AUTOSAR XML (schema 4-2-1)
package /RootP_IntDcm
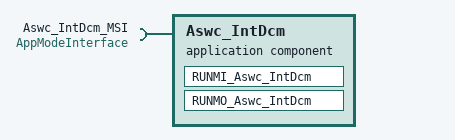
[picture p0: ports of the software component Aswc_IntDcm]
  application sw component type Aswc_IntDcm
    require port Aswc_IntDcm_MSI: required-interface=AppModeInterface
    behavior IB_Aswc_IntDcm: data-type-mapping=ApplicationModeMapping, handle-termination-and-restart=NO-SUPPORT
      swc mode switch event RUNMI_Aswc_IntDcm_NvmIn: start-on-event=RUNMI_Aswc_IntDcm, activation=ON-ENTRY, mode=Aswc_IntDcm_MSI.AppMode.APP_SYNC_INIT1
      swc mode switch event RUNMO_Aswc_IntDcm_NvmOut: start-on-event=RUNMO_Aswc_IntDcm, activation=ON-ENTRY, mode=Aswc_IntDcm_MSI.AppMode.APP_ON
      runnable RUNMI_Aswc_IntDcm
        data-write-access:
          253 x access:
            Dwa_CFG_DEF_VEHICULE: accessed-variable=PRP_SR_CFG_DEF_VEHICULE.CFG_DEF_VEHICULE
            Dwa_CFG_PRESENCE_ETSR: accessed-variable=PRP_SR_CFG_PRESENCE_ETSR.CFG_PRESENCE_ETSR
            Dwa_CFG_NAV_POI_RADAR: accessed-variable=PRP_SR_CFG_NAV_POI_RADAR.CFG_NAV_POI_RADAR
            Dwa_CFG_OPT_ANTICIPATED_PLV: accessed-variable=PRP_SR_CFG_OPT_ANTICIPATED_PLV.CFG_OPT_ANTICIPATED_PLV
            Dwa_CFG_TYPE_ILV: accessed-variable=PRP_SR_CFG_TYPE_ILV.CFG_TYPE_ILV
            Dwa_CFG_OPTION_HADC: accessed-variable=PRP_SR_CFG_OPTION_HADC.CFG_OPTION_HADC
            Dwa_CFG_TYPE_LANE_ASSIST: accessed-variable=PRP_SR_CFG_TYPE_LANE_ASSIST.CFG_TYPE_LANE_ASSIST
            Dwa_CFG_TYPE_DRIVER_ASSIST: accessed-variable=PRP_SR_CFG_TYPE_DRIVER_ASSIST.CFG_TYPE_DRIVER_ASSIST
            Dwa_CFG_PRESENCE_CABIN_AQI_SENSOR: accessed-variable=PRP_SR_CFG_PRESENCE_CABIN_AQI_SENSOR.CFG_PRESENCE_CABIN_AQI_SENSOR
            Dwa_CFG_MODUL_STTCONFORT: accessed-variable=PRP_SR_CFG_MODUL_STTCONFORT.CFG_MODUL_STTCONFORT
            Dwa_CFG_RAPENTR: accessed-variable=PRP_SR_CFG_RAPENTR.CFG_RAPENTR
            Dwa_CFG_MODUL_POLLUT: accessed-variable=PRP_SR_CFG_MODUL_POLLUT.CFG_MODUL_POLLUT
            Dwa_CFG_MODUL_CPR: accessed-variable=PRP_SR_CFG_MODUL_CPR.CFG_MODUL_CPR
            Dwa_CFG_MODUL_CTP: accessed-variable=PRP_SR_CFG_MODUL_CTP.CFG_MODUL_CTP
            Dwa_CFG_MODUL_DEBIT_AERO: accessed-variable=PRP_SR_CFG_MODUL_DEBIT_AERO.CFG_MODUL_DEBIT_AERO
            Dwa_CFG_MODUL_FMUX: accessed-variable=PRP_SR_CFG_MODUL_FMUX.CFG_MODUL_FMUX
            Dwa_CFG_MODUL_RECHAUFFEUR: accessed-variable=PRP_SR_CFG_MODUL_RECHAUFFEUR.CFG_MODUL_RECHAUFFEUR
            Dwa_CFG_MODUL_PROG_PRECOND: accessed-variable=PRP_SR_CFG_MODUL_PROG_PRECOND.CFG_MODUL_PROG_PRECOND
            Dwa_CFG_PRESENCE_CIELO: accessed-variable=PRP_SR_CFG_PRESENCE_CIELO.CFG_PRESENCE_CIELO
            Dwa_CFG_MODUL_TAS: accessed-variable=PRP_SR_CFG_MODUL_TAS.CFG_MODUL_TAS
            Dwa_CFG_MODUL_SOL: accessed-variable=PRP_SR_CFG_MODUL_SOL.CFG_MODUL_SOL
            Dwa_CFG_MODUL_DCT: accessed-variable=PRP_SR_CFG_MODUL_DCT.CFG_MODUL_DCT
            Dwa_CFG_TYPE_CLIM: accessed-variable=PRP_SR_CFG_TYPE_CLIM.CFG_TYPE_CLIM
            Dwa_CFG_TYPE_ARCHI_IHM_CLIM: accessed-variable=PRP_SR_CFG_TYPE_ARCHI_IHM_CLIM.CFG_TYPE_ARCHI_IHM_CLIM
            Dwa_CFG_TYPE_IHM_DISTRIB_AV_TACT: accessed-variable=PRP_SR_CFG_TYPE_IHM_DISTRIB_AV_TACT.CFG_TYPE_IHM_DISTRIB_AV_TACT
            Dwa_CFG_TYPE_IHM_ENTREE_AIR_PHYS: accessed-variable=PRP_SR_CFG_TYPE_IHM_ENTREE_AIR_PHYS.CFG_TYPE_IHM_ENTREE_AIR_PHYS
            Dwa_CFG_TYPE_IHM_PULSEUR_AR: accessed-variable=PRP_SR_CFG_TYPE_IHM_PULSEUR_AR.CFG_TYPE_IHM_PULSEUR_AR
            Dwa_CFG_TYPE_IHM_PULSEUR_AV_PHYS: accessed-variable=PRP_SR_CFG_TYPE_IHM_PULSEUR_AV_PHYS.CFG_TYPE_IHM_PULSEUR_AV_PHYS
            Dwa_CFG_TYPE_IHM_PULSEUR_AV_TACT: accessed-variable=PRP_SR_CFG_TYPE_IHM_PULSEUR_AV_TACT.CFG_TYPE_IHM_PULSEUR_AV_TACT
            Dwa_CFG_TYPE_IHM_PULSEUR_RG3: accessed-variable=PRP_SR_CFG_TYPE_IHM_PULSEUR_RG3.CFG_TYPE_IHM_PULSEUR_RG3
            Dwa_CFG_TYPE_IHM_TEMP_AV_PHYS: accessed-variable=PRP_SR_CFG_TYPE_IHM_TEMP_AV_PHYS.CFG_TYPE_IHM_TEMP_AV_PHYS
            Dwa_CFG_TYPE_IHM_TEMP_AV_TACT: accessed-variable=PRP_SR_CFG_TYPE_IHM_TEMP_AV_TACT.CFG_TYPE_IHM_TEMP_AV_TACT
            Dwa_CFG_TYPE_IHM_TYPAGE_AUTO: accessed-variable=PRP_SR_CFG_TYPE_IHM_TYPAGE_AUTO.CFG_TYPE_IHM_TYPAGE_AUTO
            Dwa_CFG_TYPE_FAP: accessed-variable=PRP_SR_CFG_TYPE_FAP.CFG_TYPE_FAP
            Dwa_CFG_NumTable_NH: accessed-variable=PRP_SR_CFG_NumTable_NH.CFG_NumTable_NH
            Dwa_CFG_ORIGINE_NHUILE: accessed-variable=PRP_SR_CFG_ORIGINE_NHUILE.CFG_ORIGINE_NHUILE
            Dwa_CFG_PRESENCE_AUTO_INHIB_RBG_PASS: accessed-variable=PRP_SR_CFG_PRESENCE_AUTO_INHIB_RBG_PASS.CFG_PRESENCE_AUTO_INHIB_RBG_PASS
            Dwa_CFG_PRESENCE_DSG: accessed-variable=PRP_SR_CFG_PRESENCE_DSG.CFG_PRESENCE_DSG
            Dwa_CFG_TYPE_PUSH_DSGI: accessed-variable=PRP_SR_CFG_TYPE_PUSH_DSGI.CFG_TYPE_PUSH_DSGI
            Dwa_CFG_PRESENCE_AVE: accessed-variable=PRP_SR_CFG_PRESENCE_AVE.CFG_PRESENCE_AVE
            Dwa_CFG_TYPE_CHAINE_TRACTION: accessed-variable=PRP_SR_CFG_TYPE_CHAINE_TRACTION.CFG_TYPE_CHAINE_TRACTION
            Dwa_CFG_TYPE_DEMARRAGE: accessed-variable=PRP_SR_CFG_TYPE_DEMARRAGE.CFG_TYPE_DEMARRAGE
            Dwa_CFG_TYPE_GMP: accessed-variable=PRP_SR_CFG_TYPE_GMP.CFG_TYPE_GMP
            Dwa_CFG_PRESENCE_FARC: accessed-variable=PRP_SR_CFG_PRESENCE_FARC.CFG_PRESENCE_FARC
            Dwa_CFG_PRESENCE_ARC: accessed-variable=PRP_SR_CFG_PRESENCE_ARC.CFG_PRESENCE_ARC
            Dwa_CFG_AMVAR: accessed-variable=PRP_SR_CFG_AMVAR.CFG_AMVAR
            Dwa_TYPE_HMI_MODE_SELECTOR: accessed-variable=PRP_SR_TYPE_HMI_MODE_SELECTOR.TYPE_HMI_MODE_SELECTOR
            Dwa_CFG_PRESENCE_MODE_ECO_DYN: accessed-variable=PRP_SR_CFG_PRESENCE_MODE_ECO_DYN.CFG_PRESENCE_MODE_ECO_DYN
            Dwa_CFG_PRESENCE_MEAP: accessed-variable=PRP_SR_CFG_PRESENCE_MEAP.CFG_PRESENCE_MEAP
            Dwa_CFG_POLYSENSORIAL_PACK: accessed-variable=PRP_SR_CFG_POLYSENSORIAL_PACK.CFG_POLYSENSORIAL_PACK
            Dwa_CFG_PRESENCE_MODE_SPORT_DYN: accessed-variable=PRP_SR_CFG_PRESENCE_MODE_SPORT_DYN.CFG_PRESENCE_MODE_SPORT_DYN
            Dwa_CFG_OPTION_SONDE_EAU_GAZOLE: accessed-variable=PRP_SR_CFG_OPTION_SONDE_EAU_GAZOLE.CFG_OPTION_SONDE_EAU_GAZOLE
            Dwa_CFG_TYPE_PACK_DYN: accessed-variable=PRP_SR_CFG_TYPE_PACK_DYN.CFG_TYPE_PACK_DYN
            Dwa_CFG_AUTOR_MAP_HMI: accessed-variable=PRP_SR_CFG_AUTOR_MAP_HMI.CFG_AUTOR_MAP_HMI
            Dwa_CFG_FCT_GSI: accessed-variable=PRP_SR_CFG_FCT_GSI.CFG_FCT_GSI
            Dwa_CFG_TYPE_BOITE: accessed-variable=PRP_SR_CFG_TYPE_BOITE.CFG_TYPE_BOITE
            Dwa_CFG_TYPE_SC: accessed-variable=PRP_SR_CFG_TYPE_SC.CFG_TYPE_SC
            Dwa_CFG_ACQ_PUSH_ESP: accessed-variable=PRP_SR_CFG_ACQ_PUSH_ESP.CFG_ACQ_PUSH_ESP
            Dwa_CFG_PRESENCE_ASR_PLUS: accessed-variable=PRP_SR_CFG_PRESENCE_ASR_PLUS.CFG_PRESENCE_ASR_PLUS
            Dwa_CFG_OPTION_HBB_HBC: accessed-variable=PRP_SR_CFG_OPTION_HBB_HBC.CFG_OPTION_HBB_HBC
            Dwa_CFG_OPTION_PLV: accessed-variable=PRP_SR_CFG_OPTION_PLV.CFG_OPTION_PLV
            Dwa_CFG_PRESENCE_LVVRVV: accessed-variable=PRP_SR_CFG_PRESENCE_LVVRVV.CFG_PRESENCE_LVVRVV
            Dwa_CFG_TYPE_ACC: accessed-variable=PRP_SR_CFG_TYPE_ACC.CFG_TYPE_ACC
            Dwa_CFG_TYPE_TARGET_DETECTION: accessed-variable=PRP_SR_CFG_TYPE_TARGET_DETECTION.CFG_TYPE_TARGET_DETECTION
            Dwa_CFG_TYPE_AQUI_PUSH_STT: accessed-variable=PRP_SR_CFG_TYPE_AQUI_PUSH_STT.CFG_TYPE_AQUI_PUSH_STT
            Dwa_CFG_TYPE_STT: accessed-variable=PRP_SR_CFG_TYPE_STT.CFG_TYPE_STT
            Dwa_CFG_TypeCPK: accessed-variable=PRP_SR_CFG_TypeCPK.CFG_TypeCPK
            Dwa_CFG_OPTION_SAM: accessed-variable=PRP_SR_CFG_OPTION_SAM.CFG_OPTION_SAM
            Dwa_CFG_PRESENCE_PUSH_SAM: accessed-variable=PRP_SR_CFG_PRESENCE_PUSH_SAM.CFG_PRESENCE_PUSH_SAM
            Dwa_CFG_OPTION_DOP: accessed-variable=PRP_SR_CFG_OPTION_DOP.CFG_OPTION_DOP
            Dwa_CFG_PRESENCE_ECOACH: accessed-variable=PRP_SR_CFG_PRESENCE_ECOACH.CFG_PRESENCE_ECOACH
            Dwa_CFG_NIV_ALERTE_MINI_CARB: accessed-variable=PRP_SR_CFG_NIV_ALERTE_MINI_CARB.CFG_NIV_ALERTE_MINI_CARB
            Dwa_C7D_NIV_CARB_CRITIQUE: accessed-variable=PRP_SR_C7D_NIV_CARB_CRITIQUE.C7D_NIV_CARB_CRITIQUE
            Dwa_CFG_NUM_TABLE_CARB: accessed-variable=PRP_SR_CFG_NUM_TABLE_CARB.CFG_NUM_TABLE_CARB
            Dwa_CfgTypeLocksSteering: accessed-variable=PRP_SR_CfgTypeLocksSteering.CfgTypeLocksSteering
            Dwa_CFG_OPTION_BLUETOOTH: accessed-variable=PRP_SR_CFG_OPTION_BLUETOOTH.CFG_OPTION_BLUETOOTH
            Dwa_CFG_OPTION_BAA: accessed-variable=PRP_SR_CFG_OPTION_BAA.CFG_OPTION_BAA
            Dwa_CfgTypeTrunkPushInterior: accessed-variable=PRP_SR_CfgTypeTrunkPushInterior.CfgTypeTrunkPushInterior
            Dwa_CfgTypeRearOpening: accessed-variable=PRP_SR_CfgTypeRearOpening.CfgTypeRearOpening
            Dwa_CFG_VOLET_MOTORISE: accessed-variable=PRP_SR_CFG_VOLET_MOTORISE.CFG_VOLET_MOTORISE
            Dwa_CfgSelectivityDoors: accessed-variable=PRP_SR_CfgSelectivityDoors.CfgSelectivityDoors
            Dwa_CFG_STEERING_WHEEL_POSITION: accessed-variable=PRP_SR_CFG_STEERING_WHEEL_POSITION.CFG_STEERING_WHEEL_POSITION
            Dwa_CFG_CONDA: accessed-variable=PRP_SR_CFG_CONDA.CFG_CONDA
            Dwa_CFG_PLIP_TOUCH_3_FUNCTION: accessed-variable=PRP_SR_CFG_PLIP_TOUCH_3_FUNCTION.CFG_PLIP_TOUCH_3_FUNCTION
            Dwa_CFG_PLIP_WL_FUNCTIONNALITY: accessed-variable=PRP_SR_CFG_PLIP_WL_FUNCTIONNALITY.CFG_PLIP_WL_FUNCTIONNALITY
            Dwa_CFG_PLIP_WL_BEHAVIOR: accessed-variable=PRP_SR_CFG_PLIP_WL_BEHAVIOR.CFG_PLIP_WL_BEHAVIOR
            Dwa_CFG_PLIP_PRESS_TYPE_TOUCH_3: accessed-variable=PRP_SR_CFG_PLIP_PRESS_TYPE_TOUCH_3.CFG_PLIP_PRESS_TYPE_TOUCH_3
            Dwa_CFG_DRIVER_LOCK_TYPE: accessed-variable=PRP_SR_CFG_DRIVER_LOCK_TYPE.CFG_DRIVER_LOCK_TYPE
            Dwa_CFG_FUEL_FLAP_LOCK_TYPE: accessed-variable=PRP_SR_CFG_FUEL_FLAP_LOCK_TYPE.CFG_FUEL_FLAP_LOCK_TYPE
            Dwa_CFG_HOOD_LOCK_TYPE: accessed-variable=PRP_SR_CFG_HOOD_LOCK_TYPE.CFG_HOOD_LOCK_TYPE
            Dwa_CFG_REAR_LEFT_LOCK_TYPE: accessed-variable=PRP_SR_CFG_REAR_LEFT_LOCK_TYPE.CFG_REAR_LEFT_LOCK_TYPE
            Dwa_CFG_REAR_RIGHT_LOCK_TYPE: accessed-variable=PRP_SR_CFG_REAR_RIGHT_LOCK_TYPE.CFG_REAR_RIGHT_LOCK_TYPE
            Dwa_CFG_OPTION_SUNROOF: accessed-variable=PRP_SR_CFG_OPTION_SUNROOF.CFG_OPTION_SUNROOF
            Dwa_CfgRearViewMirrorIndexingReverseGear: accessed-variable=PRP_SR_CfgRearViewMirrorIndexingReverseGear.CfgRearViewMirrorIndexingReverseGear
            Dwa_CFG_OPTION_SIEGE_CLIM: accessed-variable=PRP_SR_CFG_OPTION_SIEGE_CLIM.CFG_OPTION_SIEGE_CLIM
            Dwa_CFG_PRES_VOLANT_CHAUF: accessed-variable=PRP_SR_CFG_PRES_VOLANT_CHAUF.CFG_PRES_VOLANT_CHAUF
            Dwa_CFG_TYPE_SOC: accessed-variable=PRP_SR_CFG_TYPE_SOC.CFG_TYPE_SOC
            Dwa_CFG_OPTION_VISION_NOCTURNE: accessed-variable=PRP_SR_CFG_OPTION_VISION_NOCTURNE.CFG_OPTION_VISION_NOCTURNE
            Dwa_CFG_AUTOR_MAP_ECLI: accessed-variable=PRP_SR_CFG_AUTOR_MAP_ECLI.CFG_AUTOR_MAP_ECLI
            Dwa_CFG_POLYCHROME_AMB: accessed-variable=PRP_SR_CFG_POLYCHROME_AMB.CFG_POLYCHROME_AMB
            Dwa_CFG_OPTION_AFS: accessed-variable=PRP_SR_CFG_OPTION_AFS.CFG_OPTION_AFS
            Dwa_CFG_OPTION_ECL_INTERSEC: accessed-variable=PRP_SR_CFG_OPTION_ECL_INTERSEC.CFG_OPTION_ECL_INTERSEC
            Dwa_CFG_OPTION_ECL_VIR_STAT: accessed-variable=PRP_SR_CFG_OPTION_ECL_VIR_STAT.CFG_OPTION_ECL_VIR_STAT
            Dwa_CFG_OPTION_ANTIBR_AV: accessed-variable=PRP_SR_CFG_OPTION_ANTIBR_AV.CFG_OPTION_ANTIBR_AV
            Dwa_CFG_TypeEclairageAV: accessed-variable=PRP_SR_CFG_TypeEclairageAV.CFG_TypeEclairageAV
            Dwa_CFG_PRESENCE_BSG_RQ: accessed-variable=PRP_SR_CFG_PRESENCE_BSG_RQ.CFG_PRESENCE_BSG_RQ
            Dwa_CFG_INHIB_MOVING_EFFECT: accessed-variable=PRP_SR_CFG_INHIB_MOVING_EFFECT.CFG_INHIB_MOVING_EFFECT
            Dwa_CFG_FONCTION_AHB: accessed-variable=PRP_SR_CFG_FONCTION_AHB.CFG_FONCTION_AHB
            Dwa_CFG_OPTION_AAF: accessed-variable=PRP_SR_CFG_OPTION_AAF.CFG_OPTION_AAF
            Dwa_CFG_TYPE_COMODO: accessed-variable=PRP_SR_CFG_TYPE_COMODO.CFG_TYPE_COMODO
            Dwa_CFG_Barrette_TNB_sur_LIN: accessed-variable=PRP_SR_CFG_Barrette_TNB_sur_LIN.CFG_Barrette_TNB_sur_LIN
            Dwa_CFG_INHIB_DIAG_TNB_COND: accessed-variable=PRP_SR_CFG_INHIB_DIAG_TNB_COND.CFG_INHIB_DIAG_TNB_COND
            Dwa_CFG_INHIB_DIAG_TNB_PAR2C: accessed-variable=PRP_SR_CFG_INHIB_DIAG_TNB_PAR2C.CFG_INHIB_DIAG_TNB_PAR2C
            Dwa_CFG_INHIB_DIAG_TNB_PAR2D: accessed-variable=PRP_SR_CFG_INHIB_DIAG_TNB_PAR2D.CFG_INHIB_DIAG_TNB_PAR2D
            Dwa_CFG_INHIB_DIAG_TNB_PAR2G: accessed-variable=PRP_SR_CFG_INHIB_DIAG_TNB_PAR2G.CFG_INHIB_DIAG_TNB_PAR2G
            Dwa_CFG_OPTION_TAXI: accessed-variable=PRP_SR_CFG_OPTION_TAXI.CFG_OPTION_TAXI
            Dwa_CFG_INHIB_DIAG_TNB_PAV: accessed-variable=PRP_SR_CFG_INHIB_DIAG_TNB_PAV.CFG_INHIB_DIAG_TNB_PAV
            Dwa_CFG_NAPPE_DETECTION_PASS: accessed-variable=PRP_SR_CFG_NAPPE_DETECTION_PASS.CFG_NAPPE_DETECTION_PASS
            Dwa_CFG_NBR_CNB: accessed-variable=PRP_SR_CFG_NBR_CNB.CFG_NBR_CNB
            Dwa_CFG_TYPE_PRES_PASS_SENSOR: accessed-variable=PRP_SR_CFG_TYPE_PRES_PASS_SENSOR.CFG_TYPE_PRES_PASS_SENSOR
            Dwa_CFG_PRESENCE_OPTION_MEMORISATION: accessed-variable=PRP_SR_CFG_PRESENCE_OPTION_MEMORISATION.CFG_PRESENCE_OPTION_MEMORISATION
            Dwa_CFG_WELCOME_DRIVER_SEAT_FUNCTION: accessed-variable=PRP_SR_CFG_WELCOME_DRIVER_SEAT_FUNCTION.CFG_WELCOME_DRIVER_SEAT_FUNCTION
            Dwa_CFG_OPTION_MASSAGE: accessed-variable=PRP_SR_CFG_OPTION_MASSAGE.CFG_OPTION_MASSAGE
            Dwa_CFG_PRESENCE_VTH: accessed-variable=PRP_SR_CFG_PRESENCE_VTH.CFG_PRESENCE_VTH
            Dwa_CFG_MEMO_REGL_RETROS: accessed-variable=PRP_SR_CFG_MEMO_REGL_RETROS.CFG_MEMO_REGL_RETROS
            Dwa_CFG_PRESENCE_PBC: accessed-variable=PRP_SR_CFG_PRESENCE_PBC.CFG_PRESENCE_PBC
            Dwa_CFG_CLIMAT: accessed-variable=PRP_SR_CFG_CLIMAT.CFG_CLIMAT
            Dwa_CfgTypeFrontDefrost: accessed-variable=PRP_SR_CfgTypeFrontDefrost.CfgTypeFrontDefrost
            Dwa_CFG_TYPE_MODUL_OPTI_VIDE: accessed-variable=PRP_SR_CFG_TYPE_MODUL_OPTI_VIDE.CFG_TYPE_MODUL_OPTI_VIDE
            Dwa_CfgSweepingCourtesy: accessed-variable=PRP_SR_CfgSweepingCourtesy.CfgSweepingCourtesy
            Dwa_CfgRainSensor: accessed-variable=PRP_SR_CfgRainSensor.CfgRainSensor
            Dwa_SCR_AFFICH_POI_ADBLUE: accessed-variable=PRP_SR_SCR_AFFICH_POI_ADBLUE.SCR_AFFICH_POI_ADBLUE
            Dwa_CFG_PRESENCE_SCR: accessed-variable=PRP_SR_CFG_PRESENCE_SCR.CFG_PRESENCE_SCR
            Dwa_CFG_DISPO_PSEUDO_CONSO_CARB: accessed-variable=PRP_SR_CFG_DISPO_PSEUDO_CONSO_CARB.CFG_DISPO_PSEUDO_CONSO_CARB
            Dwa_CFG_EngineMaintType: accessed-variable=PRP_SR_CFG_EngineMaintType.CFG_EngineMaintType
            Dwa_M230_TimeFirstMaint: accessed-variable=PRP_SR_M230_TimeFirstMaint.M230_TimeFirstMaint
            Dwa_M230_TimeOtherMaint: accessed-variable=PRP_SR_M230_TimeOtherMaint.M230_TimeOtherMaint
            Dwa_M230_KmFirstMaint: accessed-variable=PRP_SR_M230_KmFirstMaint.M230_KmFirstMaint
            Dwa_M230_KmOtherMaint: accessed-variable=PRP_SR_M230_KmOtherMaint.M230_KmOtherMaint
            Dwa_M230_KmOrTimeMaint: accessed-variable=PRP_SR_M230_KmOrTimeMaint.M230_KmOrTimeMaint
            Dwa_CFG_DISTRACTION_MODE: accessed-variable=PRP_SR_CFG_DISTRACTION_MODE.CFG_DISTRACTION_MODE
            Dwa_CFG_PresenceCRT: accessed-variable=PRP_SR_CFG_PresenceCRT.CFG_PresenceCRT
            Dwa_CFG_TYPE_BTEL: accessed-variable=PRP_SR_CFG_TYPE_BTEL.CFG_TYPE_BTEL
            Dwa_CFG_SOFTWARE_UPDATE_CAPABILITY: accessed-variable=PRP_SR_CFG_SOFTWARE_UPDATE_CAPABILITY.CFG_SOFTWARE_UPDATE_CAPABILITY
            Dwa_DiagCodeVIN_01: accessed-variable=PRP_SR_DiagCodeVIN.DiagCodeVIN_{01..17}
            Dwa_CFG_SMARTDEVICE_BY_SDCM: accessed-variable=PRP_SR_CFG_SMARTDEVICE_BY_SDCM.CFG_SMARTDEVICE_BY_SDCM
            Dwa_CFG_AUTOR_MAP_INVIO: accessed-variable=PRP_SR_CFG_AUTOR_MAP_INVIO.CFG_AUTOR_MAP_INVIO
            Dwa_CFG_GEN_RSK16: accessed-variable=PRP_SR_CFG_GEN_RSK16.CFG_GEN_RSK16
            Dwa_CFG_OPTION_WLC: accessed-variable=PRP_SR_CFG_OPTION_WLC.CFG_OPTION_WLC
            Dwa_CFG_TYPE_CLE: accessed-variable=PRP_SR_CFG_TYPE_CLE.CFG_TYPE_CLE
            Dwa_CFG_ALARME_2NDE_MONTE: accessed-variable=PRP_SR_CFG_ALARME_2NDE_MONTE.CFG_ALARME_2NDE_MONTE
            Dwa_CFG_INHIB_VOLUMETRIE: accessed-variable=PRP_SR_CFG_INHIB_VOLUMETRIE.CFG_INHIB_VOLUMETRIE
            Dwa_CFG_PRESENCE_MUS_LIN: accessed-variable=PRP_SR_CFG_PRESENCE_MUS_LIN.CFG_PRESENCE_MUS_LIN
            Dwa_CFG_PRESENCE_SIRENE_LIN: accessed-variable=PRP_SR_CFG_PRESENCE_SIRENE_LIN.CFG_PRESENCE_SIRENE_LIN
            Dwa_CFG_TYPE_ALARME: accessed-variable=PRP_SR_CFG_TYPE_ALARME.CFG_TYPE_ALARME
            Dwa_CFG_OPTIONS_TLM: accessed-variable=PRP_SR_CFG_OPTIONS_TLM.CFG_OPTIONS_TLM
            Dwa_CFG_PROCESS_USINE_{01..06}: accessed-variable=PRP_SR_CFG_PROCESS_USINE_{01..06}.CFG_PROCESS_USINE_{01..06}
            Dwa_CFG_DATE_TELECODAGE_1: accessed-variable=PRP_SR_CFG_DATE_TELECODAGE_{1..3}.CFG_DATE_TELECODAGE_{1..3}
            Dwa_CFG_DATE_TELECODAGE_1: accessed-variable=PRP_SR_CFG_SIGNATURE_OUTIL_{1..3}.CFG_SIGNATURE_OUTIL_{1..3}
            Dwa_CFG_DATE_TELECODAGE_1: accessed-variable=PRP_SR_CFG_SITE_TELECODAGE.CFG_SITE_TELECODAGE
            Dwa_CFG_UCE_{001..026}: accessed-variable=PRP_SR_CFG_UCE_{001..026}.CFG_UCE_{001..026}
            Dwa_CFG_UCE_{028..069}: accessed-variable=PRP_SR_CFG_UCE_{028..069}.CFG_UCE_{028..069}
      runnable RUNMO_Aswc_IntDcm
        data-read-access:
          253 x access:
            Dra_CFG_DEF_VEHICULE: accessed-variable=PRP_SR_CFG_DEF_VEHICULE.CFG_DEF_VEHICULE
            Dra_CFG_PRESENCE_ETSR: accessed-variable=PRP_SR_CFG_PRESENCE_ETSR.CFG_PRESENCE_ETSR
            Dra_CFG_NAV_POI_RADAR: accessed-variable=PRP_SR_CFG_NAV_POI_RADAR.CFG_NAV_POI_RADAR
            Dra_CFG_OPT_ANTICIPATED_PLV: accessed-variable=PRP_SR_CFG_OPT_ANTICIPATED_PLV.CFG_OPT_ANTICIPATED_PLV
            Dra_CFG_TYPE_ILV: accessed-variable=PRP_SR_CFG_TYPE_ILV.CFG_TYPE_ILV
            Dra_CFG_OPTION_HADC: accessed-variable=PRP_SR_CFG_OPTION_HADC.CFG_OPTION_HADC
            Dra_CFG_TYPE_LANE_ASSIST: accessed-variable=PRP_SR_CFG_TYPE_LANE_ASSIST.CFG_TYPE_LANE_ASSIST
            Dra_CFG_TYPE_DRIVER_ASSIST: accessed-variable=PRP_SR_CFG_TYPE_DRIVER_ASSIST.CFG_TYPE_DRIVER_ASSIST
            Dra_CFG_PRESENCE_CABIN_AQI_SENSOR: accessed-variable=PRP_SR_CFG_PRESENCE_CABIN_AQI_SENSOR.CFG_PRESENCE_CABIN_AQI_SENSOR
            Dra_CFG_MODUL_STTCONFORT: accessed-variable=PRP_SR_CFG_MODUL_STTCONFORT.CFG_MODUL_STTCONFORT
            Dra_CFG_RAPENTR: accessed-variable=PRP_SR_CFG_RAPENTR.CFG_RAPENTR
            Dra_CFG_MODUL_POLLUT: accessed-variable=PRP_SR_CFG_MODUL_POLLUT.CFG_MODUL_POLLUT
            Dra_CFG_MODUL_CPR: accessed-variable=PRP_SR_CFG_MODUL_CPR.CFG_MODUL_CPR
            Dra_CFG_MODUL_CTP: accessed-variable=PRP_SR_CFG_MODUL_CTP.CFG_MODUL_CTP
            Dra_CFG_MODUL_DEBIT_AERO: accessed-variable=PRP_SR_CFG_MODUL_DEBIT_AERO.CFG_MODUL_DEBIT_AERO
            Dra_CFG_MODUL_FMUX: accessed-variable=PRP_SR_CFG_MODUL_FMUX.CFG_MODUL_FMUX
            Dra_CFG_MODUL_RECHAUFFEUR: accessed-variable=PRP_SR_CFG_MODUL_RECHAUFFEUR.CFG_MODUL_RECHAUFFEUR
            Dra_CFG_MODUL_PROG_PRECOND: accessed-variable=PRP_SR_CFG_MODUL_PROG_PRECOND.CFG_MODUL_PROG_PRECOND
            Dra_CFG_PRESENCE_CIELO: accessed-variable=PRP_SR_CFG_PRESENCE_CIELO.CFG_PRESENCE_CIELO
            Dra_CFG_MODUL_TAS: accessed-variable=PRP_SR_CFG_MODUL_TAS.CFG_MODUL_TAS
            Dra_CFG_MODUL_SOL: accessed-variable=PRP_SR_CFG_MODUL_SOL.CFG_MODUL_SOL
            Dra_CFG_MODUL_DCT: accessed-variable=PRP_SR_CFG_MODUL_DCT.CFG_MODUL_DCT
            Dra_CFG_TYPE_CLIM: accessed-variable=PRP_SR_CFG_TYPE_CLIM.CFG_TYPE_CLIM
            Dra_CFG_TYPE_ARCHI_IHM_CLIM: accessed-variable=PRP_SR_CFG_TYPE_ARCHI_IHM_CLIM.CFG_TYPE_ARCHI_IHM_CLIM
            Dra_CFG_TYPE_IHM_DISTRIB_AV_TACT: accessed-variable=PRP_SR_CFG_TYPE_IHM_DISTRIB_AV_TACT.CFG_TYPE_IHM_DISTRIB_AV_TACT
            Dra_CFG_TYPE_IHM_ENTREE_AIR_PHYS: accessed-variable=PRP_SR_CFG_TYPE_IHM_ENTREE_AIR_PHYS.CFG_TYPE_IHM_ENTREE_AIR_PHYS
            Dra_CFG_TYPE_IHM_PULSEUR_AR: accessed-variable=PRP_SR_CFG_TYPE_IHM_PULSEUR_AR.CFG_TYPE_IHM_PULSEUR_AR
            Dra_CFG_TYPE_IHM_PULSEUR_AV_PHYS: accessed-variable=PRP_SR_CFG_TYPE_IHM_PULSEUR_AV_PHYS.CFG_TYPE_IHM_PULSEUR_AV_PHYS
            Dra_CFG_TYPE_IHM_PULSEUR_AV_TACT: accessed-variable=PRP_SR_CFG_TYPE_IHM_PULSEUR_AV_TACT.CFG_TYPE_IHM_PULSEUR_AV_TACT
            Dra_CFG_TYPE_IHM_PULSEUR_RG3: accessed-variable=PRP_SR_CFG_TYPE_IHM_PULSEUR_RG3.CFG_TYPE_IHM_PULSEUR_RG3
            Dra_CFG_TYPE_IHM_TEMP_AV_PHYS: accessed-variable=PRP_SR_CFG_TYPE_IHM_TEMP_AV_PHYS.CFG_TYPE_IHM_TEMP_AV_PHYS
            Dra_CFG_TYPE_IHM_TEMP_AV_TACT: accessed-variable=PRP_SR_CFG_TYPE_IHM_TEMP_AV_TACT.CFG_TYPE_IHM_TEMP_AV_TACT
            Dra_CFG_TYPE_IHM_TYPAGE_AUTO: accessed-variable=PRP_SR_CFG_TYPE_IHM_TYPAGE_AUTO.CFG_TYPE_IHM_TYPAGE_AUTO
            Dra_CFG_TYPE_FAP: accessed-variable=PRP_SR_CFG_TYPE_FAP.CFG_TYPE_FAP
            Dra_CFG_NumTable_NH: accessed-variable=PRP_SR_CFG_NumTable_NH.CFG_NumTable_NH
            Dra_CFG_ORIGINE_NHUILE: accessed-variable=PRP_SR_CFG_ORIGINE_NHUILE.CFG_ORIGINE_NHUILE
            Dra_CFG_PRESENCE_AUTO_INHIB_RBG_PASS: accessed-variable=PRP_SR_CFG_PRESENCE_AUTO_INHIB_RBG_PASS.CFG_PRESENCE_AUTO_INHIB_RBG_PASS
            Dra_CFG_PRESENCE_DSG: accessed-variable=PRP_SR_CFG_PRESENCE_DSG.CFG_PRESENCE_DSG
            Dra_CFG_TYPE_PUSH_DSGI: accessed-variable=PRP_SR_CFG_TYPE_PUSH_DSGI.CFG_TYPE_PUSH_DSGI
            Dra_CFG_PRESENCE_AVE: accessed-variable=PRP_SR_CFG_PRESENCE_AVE.CFG_PRESENCE_AVE
            Dra_CFG_TYPE_CHAINE_TRACTION: accessed-variable=PRP_SR_CFG_TYPE_CHAINE_TRACTION.CFG_TYPE_CHAINE_TRACTION
            Dra_CFG_TYPE_DEMARRAGE: accessed-variable=PRP_SR_CFG_TYPE_DEMARRAGE.CFG_TYPE_DEMARRAGE
            Dra_CFG_TYPE_GMP: accessed-variable=PRP_SR_CFG_TYPE_GMP.CFG_TYPE_GMP
            Dra_CFG_PRESENCE_FARC: accessed-variable=PRP_SR_CFG_PRESENCE_FARC.CFG_PRESENCE_FARC
            Dra_CFG_PRESENCE_ARC: accessed-variable=PRP_SR_CFG_PRESENCE_ARC.CFG_PRESENCE_ARC
            Dra_CFG_AMVAR: accessed-variable=PRP_SR_CFG_AMVAR.CFG_AMVAR
            Dra_TYPE_HMI_MODE_SELECTOR: accessed-variable=PRP_SR_TYPE_HMI_MODE_SELECTOR.TYPE_HMI_MODE_SELECTOR
            Dra_CFG_PRESENCE_MODE_ECO_DYN: accessed-variable=PRP_SR_CFG_PRESENCE_MODE_ECO_DYN.CFG_PRESENCE_MODE_ECO_DYN
            Dra_CFG_PRESENCE_MEAP: accessed-variable=PRP_SR_CFG_PRESENCE_MEAP.CFG_PRESENCE_MEAP
            Dra_CFG_POLYSENSORIAL_PACK: accessed-variable=PRP_SR_CFG_POLYSENSORIAL_PACK.CFG_POLYSENSORIAL_PACK
            Dra_CFG_PRESENCE_MODE_SPORT_DYN: accessed-variable=PRP_SR_CFG_PRESENCE_MODE_SPORT_DYN.CFG_PRESENCE_MODE_SPORT_DYN
            Dra_CFG_OPTION_SONDE_EAU_GAZOLE: accessed-variable=PRP_SR_CFG_OPTION_SONDE_EAU_GAZOLE.CFG_OPTION_SONDE_EAU_GAZOLE
            Dra_CFG_TYPE_PACK_DYN: accessed-variable=PRP_SR_CFG_TYPE_PACK_DYN.CFG_TYPE_PACK_DYN
            Dra_CFG_AUTOR_MAP_HMI: accessed-variable=PRP_SR_CFG_AUTOR_MAP_HMI.CFG_AUTOR_MAP_HMI
            Dra_CFG_FCT_GSI: accessed-variable=PRP_SR_CFG_FCT_GSI.CFG_FCT_GSI
            Dra_CFG_TYPE_BOITE: accessed-variable=PRP_SR_CFG_TYPE_BOITE.CFG_TYPE_BOITE
            Dra_CFG_TYPE_SC: accessed-variable=PRP_SR_CFG_TYPE_SC.CFG_TYPE_SC
            Dra_CFG_ACQ_PUSH_ESP: accessed-variable=PRP_SR_CFG_ACQ_PUSH_ESP.CFG_ACQ_PUSH_ESP
            Dra_CFG_PRESENCE_ASR_PLUS: accessed-variable=PRP_SR_CFG_PRESENCE_ASR_PLUS.CFG_PRESENCE_ASR_PLUS
            Dra_CFG_OPTION_HBB_HBC: accessed-variable=PRP_SR_CFG_OPTION_HBB_HBC.CFG_OPTION_HBB_HBC
            Dra_CFG_OPTION_PLV: accessed-variable=PRP_SR_CFG_OPTION_PLV.CFG_OPTION_PLV
            Dra_CFG_PRESENCE_LVVRVV: accessed-variable=PRP_SR_CFG_PRESENCE_LVVRVV.CFG_PRESENCE_LVVRVV
            Dra_CFG_TYPE_ACC: accessed-variable=PRP_SR_CFG_TYPE_ACC.CFG_TYPE_ACC
            Dra_CFG_TYPE_TARGET_DETECTION: accessed-variable=PRP_SR_CFG_TYPE_TARGET_DETECTION.CFG_TYPE_TARGET_DETECTION
            Dra_CFG_TYPE_AQUI_PUSH_STT: accessed-variable=PRP_SR_CFG_TYPE_AQUI_PUSH_STT.CFG_TYPE_AQUI_PUSH_STT
            Dra_CFG_TYPE_STT: accessed-variable=PRP_SR_CFG_TYPE_STT.CFG_TYPE_STT
            Dra_CFG_TypeCPK: accessed-variable=PRP_SR_CFG_TypeCPK.CFG_TypeCPK
            Dra_CFG_OPTION_SAM: accessed-variable=PRP_SR_CFG_OPTION_SAM.CFG_OPTION_SAM
            Dra_CFG_PRESENCE_PUSH_SAM: accessed-variable=PRP_SR_CFG_PRESENCE_PUSH_SAM.CFG_PRESENCE_PUSH_SAM
            Dra_CFG_OPTION_DOP: accessed-variable=PRP_SR_CFG_OPTION_DOP.CFG_OPTION_DOP
            Dra_CFG_PRESENCE_ECOACH: accessed-variable=PRP_SR_CFG_PRESENCE_ECOACH.CFG_PRESENCE_ECOACH
            Dra_CFG_NIV_ALERTE_MINI_CARB: accessed-variable=PRP_SR_CFG_NIV_ALERTE_MINI_CARB.CFG_NIV_ALERTE_MINI_CARB
            Dra_C7D_NIV_CARB_CRITIQUE: accessed-variable=PRP_SR_C7D_NIV_CARB_CRITIQUE.C7D_NIV_CARB_CRITIQUE
            Dra_CFG_NUM_TABLE_CARB: accessed-variable=PRP_SR_CFG_NUM_TABLE_CARB.CFG_NUM_TABLE_CARB
            Dra_CfgTypeLocksSteering: accessed-variable=PRP_SR_CfgTypeLocksSteering.CfgTypeLocksSteering
            Dra_CFG_OPTION_BLUETOOTH: accessed-variable=PRP_SR_CFG_OPTION_BLUETOOTH.CFG_OPTION_BLUETOOTH
            Dra_CFG_OPTION_BAA: accessed-variable=PRP_SR_CFG_OPTION_BAA.CFG_OPTION_BAA
            Dra_CfgTypeTrunkPushInterior: accessed-variable=PRP_SR_CfgTypeTrunkPushInterior.CfgTypeTrunkPushInterior
            Dra_CfgTypeRearOpening: accessed-variable=PRP_SR_CfgTypeRearOpening.CfgTypeRearOpening
            Dra_CFG_VOLET_MOTORISE: accessed-variable=PRP_SR_CFG_VOLET_MOTORISE.CFG_VOLET_MOTORISE
            Dra_CfgSelectivityDoors: accessed-variable=PRP_SR_CfgSelectivityDoors.CfgSelectivityDoors
            Dra_CFG_STEERING_WHEEL_POSITION: accessed-variable=PRP_SR_CFG_STEERING_WHEEL_POSITION.CFG_STEERING_WHEEL_POSITION
            Dra_CFG_CONDA: accessed-variable=PRP_SR_CFG_CONDA.CFG_CONDA
            Dra_CFG_PLIP_TOUCH_3_FUNCTION: accessed-variable=PRP_SR_CFG_PLIP_TOUCH_3_FUNCTION.CFG_PLIP_TOUCH_3_FUNCTION
            Dra_CFG_PLIP_WL_FUNCTIONNALITY: accessed-variable=PRP_SR_CFG_PLIP_WL_FUNCTIONNALITY.CFG_PLIP_WL_FUNCTIONNALITY
            Dra_CFG_PLIP_WL_BEHAVIOR: accessed-variable=PRP_SR_CFG_PLIP_WL_BEHAVIOR.CFG_PLIP_WL_BEHAVIOR
            Dra_CFG_PLIP_PRESS_TYPE_TOUCH_3: accessed-variable=PRP_SR_CFG_PLIP_PRESS_TYPE_TOUCH_3.CFG_PLIP_PRESS_TYPE_TOUCH_3
            Dra_CFG_DRIVER_LOCK_TYPE: accessed-variable=PRP_SR_CFG_DRIVER_LOCK_TYPE.CFG_DRIVER_LOCK_TYPE
            Dra_CFG_FUEL_FLAP_LOCK_TYPE: accessed-variable=PRP_SR_CFG_FUEL_FLAP_LOCK_TYPE.CFG_FUEL_FLAP_LOCK_TYPE
            Dra_CFG_HOOD_LOCK_TYPE: accessed-variable=PRP_SR_CFG_HOOD_LOCK_TYPE.CFG_HOOD_LOCK_TYPE
            Dra_CFG_REAR_LEFT_LOCK_TYPE: accessed-variable=PRP_SR_CFG_REAR_LEFT_LOCK_TYPE.CFG_REAR_LEFT_LOCK_TYPE
            Dra_CFG_REAR_RIGHT_LOCK_TYPE: accessed-variable=PRP_SR_CFG_REAR_RIGHT_LOCK_TYPE.CFG_REAR_RIGHT_LOCK_TYPE
            Dra_CFG_OPTION_SUNROOF: accessed-variable=PRP_SR_CFG_OPTION_SUNROOF.CFG_OPTION_SUNROOF
            Dra_CfgRearViewMirrorIndexingReverseGear: accessed-variable=PRP_SR_CfgRearViewMirrorIndexingReverseGear.CfgRearViewMirrorIndexingReverseGear
            Dra_CFG_OPTION_SIEGE_CLIM: accessed-variable=PRP_SR_CFG_OPTION_SIEGE_CLIM.CFG_OPTION_SIEGE_CLIM
            Dra_CFG_PRES_VOLANT_CHAUF: accessed-variable=PRP_SR_CFG_PRES_VOLANT_CHAUF.CFG_PRES_VOLANT_CHAUF
            Dra_CFG_TYPE_SOC: accessed-variable=PRP_SR_CFG_TYPE_SOC.CFG_TYPE_SOC
            Dra_CFG_OPTION_VISION_NOCTURNE: accessed-variable=PRP_SR_CFG_OPTION_VISION_NOCTURNE.CFG_OPTION_VISION_NOCTURNE
            Dra_CFG_AUTOR_MAP_ECLI: accessed-variable=PRP_SR_CFG_AUTOR_MAP_ECLI.CFG_AUTOR_MAP_ECLI
            Dra_CFG_POLYCHROME_AMB: accessed-variable=PRP_SR_CFG_POLYCHROME_AMB.CFG_POLYCHROME_AMB
            Dra_CFG_OPTION_AFS: accessed-variable=PRP_SR_CFG_OPTION_AFS.CFG_OPTION_AFS
            Dra_CFG_OPTION_ECL_INTERSEC: accessed-variable=PRP_SR_CFG_OPTION_ECL_INTERSEC.CFG_OPTION_ECL_INTERSEC
            Dra_CFG_OPTION_ECL_VIR_STAT: accessed-variable=PRP_SR_CFG_OPTION_ECL_VIR_STAT.CFG_OPTION_ECL_VIR_STAT
            Dra_CFG_OPTION_ANTIBR_AV: accessed-variable=PRP_SR_CFG_OPTION_ANTIBR_AV.CFG_OPTION_ANTIBR_AV
            Dra_CFG_TypeEclairageAV: accessed-variable=PRP_SR_CFG_TypeEclairageAV.CFG_TypeEclairageAV
            Dra_CFG_PRESENCE_BSG_RQ: accessed-variable=PRP_SR_CFG_PRESENCE_BSG_RQ.CFG_PRESENCE_BSG_RQ
            Dra_CFG_INHIB_MOVING_EFFECT: accessed-variable=PRP_SR_CFG_INHIB_MOVING_EFFECT.CFG_INHIB_MOVING_EFFECT
            Dra_CFG_FONCTION_AHB: accessed-variable=PRP_SR_CFG_FONCTION_AHB.CFG_FONCTION_AHB
            Dra_CFG_OPTION_AAF: accessed-variable=PRP_SR_CFG_OPTION_AAF.CFG_OPTION_AAF
            Dra_CFG_TYPE_COMODO: accessed-variable=PRP_SR_CFG_TYPE_COMODO.CFG_TYPE_COMODO
            Dra_CFG_Barrette_TNB_sur_LIN: accessed-variable=PRP_SR_CFG_Barrette_TNB_sur_LIN.CFG_Barrette_TNB_sur_LIN
            Dra_CFG_INHIB_DIAG_TNB_COND: accessed-variable=PRP_SR_CFG_INHIB_DIAG_TNB_COND.CFG_INHIB_DIAG_TNB_COND
            Dra_CFG_INHIB_DIAG_TNB_PAR2C: accessed-variable=PRP_SR_CFG_INHIB_DIAG_TNB_PAR2C.CFG_INHIB_DIAG_TNB_PAR2C
            Dra_CFG_INHIB_DIAG_TNB_PAR2D: accessed-variable=PRP_SR_CFG_INHIB_DIAG_TNB_PAR2D.CFG_INHIB_DIAG_TNB_PAR2D
            Dra_CFG_INHIB_DIAG_TNB_PAR2G: accessed-variable=PRP_SR_CFG_INHIB_DIAG_TNB_PAR2G.CFG_INHIB_DIAG_TNB_PAR2G
            Dra_CFG_OPTION_TAXI: accessed-variable=PRP_SR_CFG_OPTION_TAXI.CFG_OPTION_TAXI
            Dra_CFG_INHIB_DIAG_TNB_PAV: accessed-variable=PRP_SR_CFG_INHIB_DIAG_TNB_PAV.CFG_INHIB_DIAG_TNB_PAV
            Dra_CFG_NAPPE_DETECTION_PASS: accessed-variable=PRP_SR_CFG_NAPPE_DETECTION_PASS.CFG_NAPPE_DETECTION_PASS
            Dra_CFG_NBR_CNB: accessed-variable=PRP_SR_CFG_NBR_CNB.CFG_NBR_CNB
            Dra_CFG_TYPE_PRES_PASS_SENSOR: accessed-variable=PRP_SR_CFG_TYPE_PRES_PASS_SENSOR.CFG_TYPE_PRES_PASS_SENSOR
            Dra_CFG_PRESENCE_OPTION_MEMORISATION: accessed-variable=PRP_SR_CFG_PRESENCE_OPTION_MEMORISATION.CFG_PRESENCE_OPTION_MEMORISATION
            Dra_CFG_WELCOME_DRIVER_SEAT_FUNCTION: accessed-variable=PRP_SR_CFG_WELCOME_DRIVER_SEAT_FUNCTION.CFG_WELCOME_DRIVER_SEAT_FUNCTION
            Dra_CFG_OPTION_MASSAGE: accessed-variable=PRP_SR_CFG_OPTION_MASSAGE.CFG_OPTION_MASSAGE
            Dra_CFG_PRESENCE_VTH: accessed-variable=PRP_SR_CFG_PRESENCE_VTH.CFG_PRESENCE_VTH
            Dra_CFG_MEMO_REGL_RETROS: accessed-variable=PRP_SR_CFG_MEMO_REGL_RETROS.CFG_MEMO_REGL_RETROS
            Dra_CFG_PRESENCE_PBC: accessed-variable=PRP_SR_CFG_PRESENCE_PBC.CFG_PRESENCE_PBC
            Dra_CFG_CLIMAT: accessed-variable=PRP_SR_CFG_CLIMAT.CFG_CLIMAT
            Dra_CfgTypeFrontDefrost: accessed-variable=PRP_SR_CfgTypeFrontDefrost.CfgTypeFrontDefrost
            Dra_CFG_TYPE_MODUL_OPTI_VIDE: accessed-variable=PRP_SR_CFG_TYPE_MODUL_OPTI_VIDE.CFG_TYPE_MODUL_OPTI_VIDE
            Dra_CfgSweepingCourtesy: accessed-variable=PRP_SR_CfgSweepingCourtesy.CfgSweepingCourtesy
            Dra_CfgRainSensor: accessed-variable=PRP_SR_CfgRainSensor.CfgRainSensor
            Dra_SCR_AFFICH_POI_ADBLUE: accessed-variable=PRP_SR_SCR_AFFICH_POI_ADBLUE.SCR_AFFICH_POI_ADBLUE
            Dra_CFG_PRESENCE_SCR: accessed-variable=PRP_SR_CFG_PRESENCE_SCR.CFG_PRESENCE_SCR
            Dra_CFG_DISPO_PSEUDO_CONSO_CARB: accessed-variable=PRP_SR_CFG_DISPO_PSEUDO_CONSO_CARB.CFG_DISPO_PSEUDO_CONSO_CARB
            Dra_CFG_EngineMaintType: accessed-variable=PRP_SR_CFG_EngineMaintType.CFG_EngineMaintType
            Dra_M230_TimeFirstMaint: accessed-variable=PRP_SR_M230_TimeFirstMaint.M230_TimeFirstMaint
            Dra_M230_TimeOtherMaint: accessed-variable=PRP_SR_M230_TimeOtherMaint.M230_TimeOtherMaint
            Dra_M230_KmFirstMaint: accessed-variable=PRP_SR_M230_KmFirstMaint.M230_KmFirstMaint
            Dra_M230_KmOtherMaint: accessed-variable=PRP_SR_M230_KmOtherMaint.M230_KmOtherMaint
            Dra_M230_KmOrTimeMaint: accessed-variable=PRP_SR_M230_KmOrTimeMaint.M230_KmOrTimeMaint
            Dra_CFG_DISTRACTION_MODE: accessed-variable=PRP_SR_CFG_DISTRACTION_MODE.CFG_DISTRACTION_MODE
            Dra_CFG_PresenceCRT: accessed-variable=PRP_SR_CFG_PresenceCRT.CFG_PresenceCRT
            Dra_CFG_TYPE_BTEL: accessed-variable=PRP_SR_CFG_TYPE_BTEL.CFG_TYPE_BTEL
            Dra_CFG_SOFTWARE_UPDATE_CAPABILITY: accessed-variable=PRP_SR_CFG_SOFTWARE_UPDATE_CAPABILITY.CFG_SOFTWARE_UPDATE_CAPABILITY
            Dra_DiagCodeVIN_01: accessed-variable=PRP_SR_DiagCodeVIN.DiagCodeVIN_{01..17}
            Dra_CFG_SMARTDEVICE_BY_SDCM: accessed-variable=PRP_SR_CFG_SMARTDEVICE_BY_SDCM.CFG_SMARTDEVICE_BY_SDCM
            Dra_CFG_AUTOR_MAP_INVIO: accessed-variable=PRP_SR_CFG_AUTOR_MAP_INVIO.CFG_AUTOR_MAP_INVIO
            Dra_CFG_GEN_RSK16: accessed-variable=PRP_SR_CFG_GEN_RSK16.CFG_GEN_RSK16
            Dra_CFG_OPTION_WLC: accessed-variable=PRP_SR_CFG_OPTION_WLC.CFG_OPTION_WLC
            Dra_CFG_TYPE_CLE: accessed-variable=PRP_SR_CFG_TYPE_CLE.CFG_TYPE_CLE
            Dra_CFG_ALARME_2NDE_MONTE: accessed-variable=PRP_SR_CFG_ALARME_2NDE_MONTE.CFG_ALARME_2NDE_MONTE
            Dra_CFG_INHIB_VOLUMETRIE: accessed-variable=PRP_SR_CFG_INHIB_VOLUMETRIE.CFG_INHIB_VOLUMETRIE
            Dra_CFG_PRESENCE_MUS_LIN: accessed-variable=PRP_SR_CFG_PRESENCE_MUS_LIN.CFG_PRESENCE_MUS_LIN
            Dra_CFG_PRESENCE_SIRENE_LIN: accessed-variable=PRP_SR_CFG_PRESENCE_SIRENE_LIN.CFG_PRESENCE_SIRENE_LIN
            Dra_CFG_TYPE_ALARME: accessed-variable=PRP_SR_CFG_TYPE_ALARME.CFG_TYPE_ALARME
            Dra_CFG_OPTIONS_TLM: accessed-variable=PRP_SR_CFG_OPTIONS_TLM.CFG_OPTIONS_TLM
            Dra_CFG_PROCESS_USINE_{01..06}: accessed-variable=PRP_SR_CFG_PROCESS_USINE_{01..06}.CFG_PROCESS_USINE_{01..06}
            Dra_CFG_DATE_TELECODAGE_1: accessed-variable=PRP_SR_CFG_DATE_TELECODAGE_{1..3}.CFG_DATE_TELECODAGE_{1..3}
            Dra_CFG_DATE_TELECODAGE_1: accessed-variable=PRP_SR_CFG_SIGNATURE_OUTIL_{1..3}.CFG_SIGNATURE_OUTIL_{1..3}
            Dra_CFG_DATE_TELECODAGE_1: accessed-variable=PRP_SR_CFG_SITE_TELECODAGE.CFG_SITE_TELECODAGE
            Dra_CFG_UCE_{001..026}: accessed-variable=PRP_SR_CFG_UCE_{001..026}.CFG_UCE_{001..026}
            Dra_CFG_UCE_{028..069}: accessed-variable=PRP_SR_CFG_UCE_{028..069}.CFG_UCE_{028..069}
